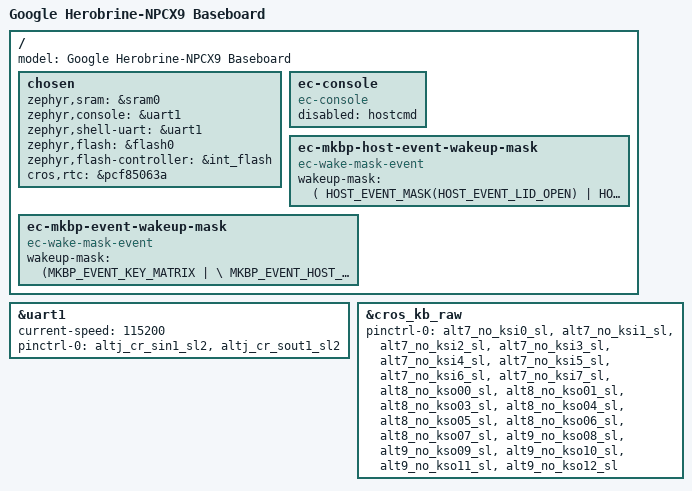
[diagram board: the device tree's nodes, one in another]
/* Copyright 2021 The Chromium OS Authors. All rights reserved.
 * Use of this source code is governed by a BSD-style license that can be
 * found in the LICENSE file.
 */

/dts-v1/;

#include <cros/nuvoton/npcx9.dtsi>
#include <dt-bindings/gpio_defines.h>
#include <dt-bindings/wake_mask_event_defines.h>
#include <nuvoton/npcx9m3f.dtsi>

/ {
	model = "Google Herobrine-NPCX9 Baseboard";

	chosen {
		zephyr,sram = &sram0;
		zephyr,console = &uart1;
		zephyr,shell-uart = &uart1;
		zephyr,flash = &flash0;
		zephyr,flash-controller = &int_flash;
		cros,rtc = &pcf85063a;
	};

	ec-console {
		compatible = "ec-console";

		disabled = "hostcmd";
	};

	ec-mkbp-host-event-wakeup-mask {
		compatible = "ec-wake-mask-event";
		wakeup-mask = <(
			HOST_EVENT_MASK(HOST_EVENT_LID_OPEN) |
			HOST_EVENT_MASK(HOST_EVENT_POWER_BUTTON) |
			HOST_EVENT_MASK(HOST_EVENT_AC_CONNECTED) |
			HOST_EVENT_MASK(HOST_EVENT_AC_DISCONNECTED) |
			HOST_EVENT_MASK(HOST_EVENT_HANG_DETECT) |
			HOST_EVENT_MASK(HOST_EVENT_RTC) |
			HOST_EVENT_MASK(HOST_EVENT_MODE_CHANGE) |
			HOST_EVENT_MASK(HOST_EVENT_DEVICE))>;
	};

	ec-mkbp-event-wakeup-mask {
		compatible = "ec-wake-mask-event";
		wakeup-mask = <(MKBP_EVENT_KEY_MATRIX | \
				MKBP_EVENT_HOST_EVENT | \
				MKBP_EVENT_SENSOR_FIFO)>;
	};

};

&uart1 {
	status = "okay";
	current-speed = <115200>;
	pinctrl-0 = <&altj_cr_sin1_sl2 &altj_cr_sout1_sl2>;
};

&cros_kb_raw {
	status = "okay";
	/* No KSO2 (it's inverted and implemented by GPIO) */
	pinctrl-0 = <&alt7_no_ksi0_sl
		     &alt7_no_ksi1_sl
		     &alt7_no_ksi2_sl
		     &alt7_no_ksi3_sl
		     &alt7_no_ksi4_sl
		     &alt7_no_ksi5_sl
		     &alt7_no_ksi6_sl
		     &alt7_no_ksi7_sl
		     &alt8_no_kso00_sl
		     &alt8_no_kso01_sl
		     &alt8_no_kso03_sl
		     &alt8_no_kso04_sl
		     &alt8_no_kso05_sl
		     &alt8_no_kso06_sl
		     &alt8_no_kso07_sl
		     &alt9_no_kso08_sl
		     &alt9_no_kso09_sl
		     &alt9_no_kso10_sl
		     &alt9_no_kso11_sl
		     &alt9_no_kso12_sl
		     >;
};
